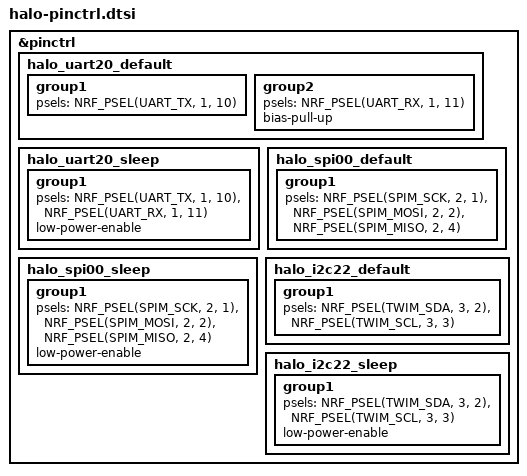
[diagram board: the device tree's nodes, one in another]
/* SPDX-License-Identifier: Apache-2.0 */

&pinctrl {
	halo_uart20_default: halo_uart20_default {
		group1 {
			psels = <NRF_PSEL(UART_TX, 1, 10)>;
		};

		group2 {
			psels = <NRF_PSEL(UART_RX, 1, 11)>;
			bias-pull-up;
		};
	};

	halo_uart20_sleep: halo_uart20_sleep {
		group1 {
			psels = <NRF_PSEL(UART_TX, 1, 10)>,
				<NRF_PSEL(UART_RX, 1, 11)>;
			low-power-enable;
		};
	};

	halo_spi00_default: halo_spi00_default {
		group1 {
			psels = <NRF_PSEL(SPIM_SCK, 2, 1)>,
				<NRF_PSEL(SPIM_MOSI, 2, 2)>,
				<NRF_PSEL(SPIM_MISO, 2, 4)>;
		};
	};

	halo_spi00_sleep: halo_spi00_sleep {
		group1 {
			psels = <NRF_PSEL(SPIM_SCK, 2, 1)>,
				<NRF_PSEL(SPIM_MOSI, 2, 2)>,
				<NRF_PSEL(SPIM_MISO, 2, 4)>;
			low-power-enable;
		};
	};

	halo_i2c22_default: halo_i2c22_default {
		group1 {
			psels = <NRF_PSEL(TWIM_SDA, 3, 2)>,
				<NRF_PSEL(TWIM_SCL, 3, 3)>;
		};
	};

	halo_i2c22_sleep: halo_i2c22_sleep {
		group1 {
			psels = <NRF_PSEL(TWIM_SDA, 3, 2)>,
				<NRF_PSEL(TWIM_SCL, 3, 3)>;
			low-power-enable;
		};
	};
};
